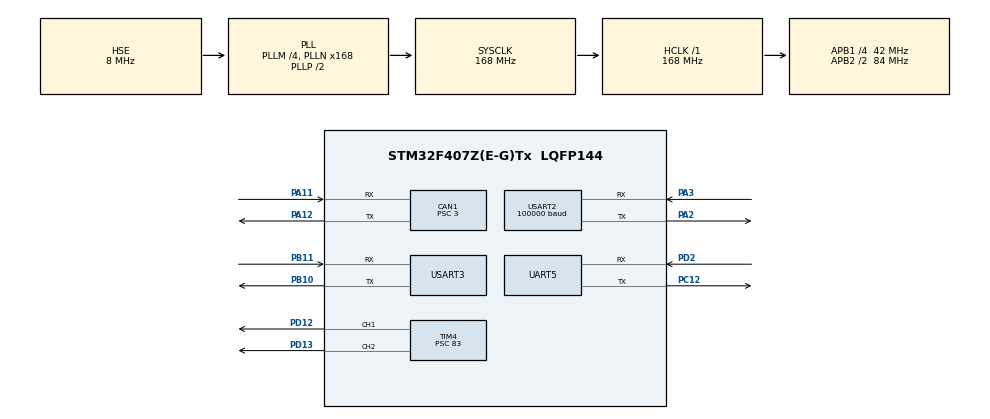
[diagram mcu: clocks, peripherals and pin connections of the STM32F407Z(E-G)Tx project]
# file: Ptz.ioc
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CAN1.ABOM=ENABLE
CAN1.BS1=CAN_BS1_9TQ
CAN1.BS2=CAN_BS2_4TQ
CAN1.CalculateTimeQuantum=71.42857142857143
CAN1.Prescaler=3
Dma.Request0=UART5_RX
Dma.Request1=UART5_TX
Dma.Request2=USART2_RX
Dma.Request3=USART3_RX
Dma.Request4=USART3_TX
Dma.UART5_RX.0.Direction=DMA_PERIPH_TO_MEMORY
Dma.UART5_RX.0.FIFOMode=DMA_FIFOMODE_DISABLE
Dma.UART5_RX.0.Instance=DMA1_Stream0
Dma.UART5_RX.0.MemDataAlignment=DMA_MDATAALIGN_BYTE
Dma.UART5_RX.0.MemInc=DMA_MINC_ENABLE
Dma.UART5_RX.0.Mode=DMA_NORMAL
Dma.UART5_RX.0.PeriphDataAlignment=DMA_PDATAALIGN_BYTE
Dma.UART5_RX.0.PeriphInc=DMA_PINC_DISABLE
Dma.UART5_RX.0.Priority=DMA_PRIORITY_LOW
Dma.UART5_TX.1.Direction=DMA_MEMORY_TO_PERIPH
Dma.UART5_TX.1.FIFOMode=DMA_FIFOMODE_DISABLE
Dma.UART5_TX.1.Instance=DMA1_Stream7
Dma.UART5_TX.1.MemDataAlignment=DMA_MDATAALIGN_BYTE
Dma.UART5_TX.1.MemInc=DMA_MINC_ENABLE
Dma.UART5_TX.1.Mode=DMA_NORMAL
Dma.UART5_TX.1.PeriphDataAlignment=DMA_PDATAALIGN_BYTE
Dma.UART5_TX.1.PeriphInc=DMA_PINC_DISABLE
Dma.UART5_TX.1.Priority=DMA_PRIORITY_LOW
Dma.USART2_RX.2.Direction=DMA_PERIPH_TO_MEMORY
Dma.USART2_RX.2.FIFOMode=DMA_FIFOMODE_DISABLE
Dma.USART2_RX.2.Instance=DMA1_Stream5
Dma.USART2_RX.2.MemDataAlignment=DMA_MDATAALIGN_BYTE
Dma.USART2_RX.2.MemInc=DMA_MINC_ENABLE
Dma.USART2_RX.2.Mode=DMA_NORMAL
Dma.USART2_RX.2.PeriphDataAlignment=DMA_PDATAALIGN_BYTE
Dma.USART2_RX.2.PeriphInc=DMA_PINC_DISABLE
Dma.USART2_RX.2.Priority=DMA_PRIORITY_LOW
Dma.USART3_RX.3.Direction=DMA_PERIPH_TO_MEMORY
Dma.USART3_RX.3.FIFOMode=DMA_FIFOMODE_DISABLE
Dma.USART3_RX.3.Instance=DMA1_Stream1
Dma.USART3_RX.3.MemDataAlignment=DMA_MDATAALIGN_BYTE
Dma.USART3_RX.3.MemInc=DMA_MINC_ENABLE
Dma.USART3_RX.3.Mode=DMA_NORMAL
Dma.USART3_RX.3.PeriphDataAlignment=DMA_PDATAALIGN_BYTE
Dma.USART3_RX.3.PeriphInc=DMA_PINC_DISABLE
Dma.USART3_RX.3.Priority=DMA_PRIORITY_LOW
Dma.USART3_TX.4.Direction=DMA_MEMORY_TO_PERIPH
Dma.USART3_TX.4.FIFOMode=DMA_FIFOMODE_DISABLE
Dma.USART3_TX.4.Instance=DMA1_Stream3
Dma.USART3_TX.4.MemDataAlignment=DMA_MDATAALIGN_BYTE
Dma.USART3_TX.4.MemInc=DMA_MINC_ENABLE
Dma.USART3_TX.4.Mode=DMA_NORMAL
Dma.USART3_TX.4.PeriphDataAlignment=DMA_PDATAALIGN_BYTE
Dma.USART3_TX.4.PeriphInc=DMA_PINC_DISABLE
Dma.USART3_TX.4.Priority=DMA_PRIORITY_LOW
Mcu.Family=STM32F4
Mcu.Name=STM32F407Z(E-G)Tx
Mcu.Package=LQFP144
NVIC.CAN1_RX0_IRQn=true\:5\:0\:true\:false\:true\:true\:true
NVIC.CAN1_TX_IRQn=true\:5\:0\:true\:false\:true\:true\:true
NVIC.DMA1_Stream0_IRQn=true\:5\:0\:true\:false\:true\:false\:true
NVIC.DMA1_Stream1_IRQn=true\:5\:0\:true\:false\:true\:false\:true
NVIC.DMA1_Stream3_IRQn=true\:5\:0\:true\:false\:true\:false\:true
NVIC.DMA1_Stream5_IRQn=true\:5\:0\:true\:false\:true\:false\:true
NVIC.DMA1_Stream7_IRQn=true\:5\:0\:true\:false\:true\:false\:true
NVIC.PriorityGroup=NVIC_PRIORITYGROUP_4
NVIC.TIM3_IRQn=true\:5\:0\:true\:false\:true\:true\:true
NVIC.TIM4_IRQn=true\:5\:0\:true\:false\:true\:true\:true
NVIC.TIM6_DAC_IRQn=true\:0\:0\:true\:false\:true\:false\:true
NVIC.TIM7_IRQn=true\:5\:0\:true\:false\:true\:true\:true
NVIC.TimeBase=TIM6_DAC_IRQn
NVIC.TimeBaseIP=TIM6
NVIC.UART5_IRQn=true\:5\:0\:true\:false\:true\:true\:true
NVIC.USART2_IRQn=true\:5\:0\:true\:false\:true\:true\:true
NVIC.USART3_IRQn=true\:5\:0\:true\:false\:true\:true\:true
PA11.Mode=Master
PA11.Signal=CAN1_RX
PA12.Mode=Master
PA12.Signal=CAN1_TX
PA2.Mode=Asynchronous
PA2.Signal=USART2_TX
PA3.Mode=Asynchronous
PA3.Signal=USART2_RX
PB10.Mode=Asynchronous
PB10.Signal=USART3_TX
PB11.Mode=Asynchronous
PB11.Signal=USART3_RX
PC12.Mode=Asynchronous
PC12.Signal=UART5_TX
PD12.Signal=S_TIM4_CH1
PD13.Signal=S_TIM4_CH2
PD2.Mode=Asynchronous
PD2.Signal=UART5_RX
PH0-OSC_IN.Mode=HSE-External-Oscillator
PH0-OSC_IN.Signal=RCC_OSC_IN
PH1-OSC_OUT.Mode=HSE-External-Oscillator
PH1-OSC_OUT.Signal=RCC_OSC_OUT
ProjectManager.HeapSize=0x200
ProjectManager.StackSize=0x400
ProjectManager.TargetToolchain=MDK-ARM V5
RCC.48MHZClocksFreq_Value=84000000
RCC.AHBFreq_Value=168000000
RCC.APB1CLKDivider=RCC_HCLK_DIV4
RCC.APB1Freq_Value=42000000
RCC.APB1TimFreq_Value=84000000
RCC.APB2CLKDivider=RCC_HCLK_DIV2
RCC.APB2Freq_Value=84000000
RCC.APB2TimFreq_Value=168000000
RCC.CortexFreq_Value=168000000
RCC.HCLKFreq_Value=168000000
RCC.HSE_VALUE=8000000
RCC.HSI_VALUE=16000000
RCC.LSE_VALUE=32768
RCC.PLLM=4
RCC.PLLN=168
RCC.PLLSourceVirtual=RCC_PLLSOURCE_HSE
RCC.SYSCLKFreq_VALUE=168000000
RCC.SYSCLKSource=RCC_SYSCLKSOURCE_PLLCLK
RCC.VCOOutputFreq_Value=336000000
SH.S_TIM4_CH1.0=TIM4_CH1,PWM Generation1 CH1
SH.S_TIM4_CH2.0=TIM4_CH2,PWM Generation2 CH2
TIM3.Period=999
TIM3.Prescaler=83
TIM4.Channel-PWM\ Generation1\ CH1=TIM_CHANNEL_1
TIM4.Channel-PWM\ Generation2\ CH2=TIM_CHANNEL_2
TIM4.Period=19999
TIM4.Prescaler=83
TIM4.Pulse-PWM\ Generation2\ CH2=16000
TIM7.Period=1000
TIM7.Prescaler=8400
UART5.VirtualMode=Asynchronous
USART2.BaudRate=100000
USART2.Parity=PARITY_EVEN
USART2.VirtualMode=VM_ASYNC
USART3.VirtualMode=VM_ASYNC
VP_SYS_VS_tim6.Mode=TIM6
VP_TIM3_VS_ClockSourceINT.Mode=Internal
VP_TIM4_VS_ClockSourceINT.Mode=Internal
VP_TIM7_VS_ClockSourceINT.Mode=Enable_Timer
board=custom

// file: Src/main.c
/* USER CODE BEGIN Header */
/**
  ******************************************************************************
  * @file           : main.c
  * @brief          : Main program body
  ******************************************************************************
  * @attention
  *
  * <h2><center>&copy; Copyright (c) 2020 STMicroelectronics.
  * All rights reserved.</center></h2>
  *
  * This software component is licensed by ST under BSD 3-Clause license,
  * the "License"; You may not use this file except in compliance with the
  * License. You may obtain a copy of the License at:
  *                        opensource.org/licenses/BSD-3-Clause
  *
  ******************************************************************************
  */
/* USER CODE END Header */

#include "main.h"
#include "can.h"
#include "dma.h"
#include "tim.h"
#include "usart.h"
#include "gpio.h"

/* USER CODE BEGIN Includes */
#include "RC_Task.h"
#include "CanBus_Task.h"
#include "shoot_task.h"
#include "Top_Gimbal.h"
#include "pid.h"

/* USER CODE END Includes */

void SystemClock_Config(void);

int main(void)
{

  /* MCU Configuration--------------------------------------------------------*/

  /* Reset of all peripherals, Initializes the Flash interface and the Systick. */
  HAL_Init();

  /* Configure the system clock */
  SystemClock_Config();

  /* Initialize all configured peripherals */
  MX_GPIO_Init();
  MX_DMA_Init();
  MX_CAN1_Init();
  MX_TIM3_Init();
  MX_TIM4_Init();
  MX_TIM7_Init();
  MX_UART5_Init();
  MX_USART2_UART_Init();
  MX_USART3_UART_Init();
  /* USER CODE BEGIN 2 */
	 HAL_UART_Receive_IT_IDLE(&huart2,UART_Buffer,100);   /*启动串口空闲中断，用于接收遥控器发来的数据*/
    Gimbal_init();
		Shoot_init();

  /* USER CODE END 2 */

  /* Infinite loop */
  while (1)
  {

    /* USER CODE BEGIN 3 */
		Gimbal_RC();
		GimbalPidCalc();
		Pluck_Control();  //拨弹遥控数据更新
		PluckPidCalc();

		Gimbal_Control();
		PluckPidCalc();

  }
  /* USER CODE END 3 */
}

void SystemClock_Config(void)
{
  RCC_OscInitTypeDef RCC_OscInitStruct = {0};
  RCC_ClkInitTypeDef RCC_ClkInitStruct = {0};

  /** Configure the main internal regulator output voltage
  */
  __HAL_RCC_PWR_CLK_ENABLE();
  __HAL_PWR_VOLTAGESCALING_CONFIG(PWR_REGULATOR_VOLTAGE_SCALE1);
  /** Initializes the CPU, AHB and APB busses clocks
  */
  RCC_OscInitStruct.OscillatorType = RCC_OSCILLATORTYPE_HSE;
  RCC_OscInitStruct.HSEState = RCC_HSE_ON;
  RCC_OscInitStruct.PLL.PLLState = RCC_PLL_ON;
  RCC_OscInitStruct.PLL.PLLSource = RCC_PLLSOURCE_HSE;
  RCC_OscInitStruct.PLL.PLLM = 4;
  RCC_OscInitStruct.PLL.PLLN = 168;
  RCC_OscInitStruct.PLL.PLLP = RCC_PLLP_DIV2;
  RCC_OscInitStruct.PLL.PLLQ = 4;
  if (HAL_RCC_OscConfig(&RCC_OscInitStruct) != HAL_OK)
  {
    Error_Handler();
  }
  /** Initializes the CPU, AHB and APB busses clocks
  */
  RCC_ClkInitStruct.ClockType = RCC_CLOCKTYPE_HCLK|RCC_CLOCKTYPE_SYSCLK
                              |RCC_CLOCKTYPE_PCLK1|RCC_CLOCKTYPE_PCLK2;
  RCC_ClkInitStruct.SYSCLKSource = RCC_SYSCLKSOURCE_PLLCLK;
  RCC_ClkInitStruct.AHBCLKDivider = RCC_SYSCLK_DIV1;
  RCC_ClkInitStruct.APB1CLKDivider = RCC_HCLK_DIV4;
  RCC_ClkInitStruct.APB2CLKDivider = RCC_HCLK_DIV2;

  if (HAL_RCC_ClockConfig(&RCC_ClkInitStruct, FLASH_LATENCY_5) != HAL_OK)
  {
    Error_Handler();
  }
}

void HAL_TIM_PeriodElapsedCallback(TIM_HandleTypeDef *htim)
{
  if (htim->Instance == TIM6) {
    HAL_IncTick();
  }
}

void Error_Handler(void)
{
}

/************************ (C) COPYRIGHT STMicroelectronics *****END OF FILE****/
